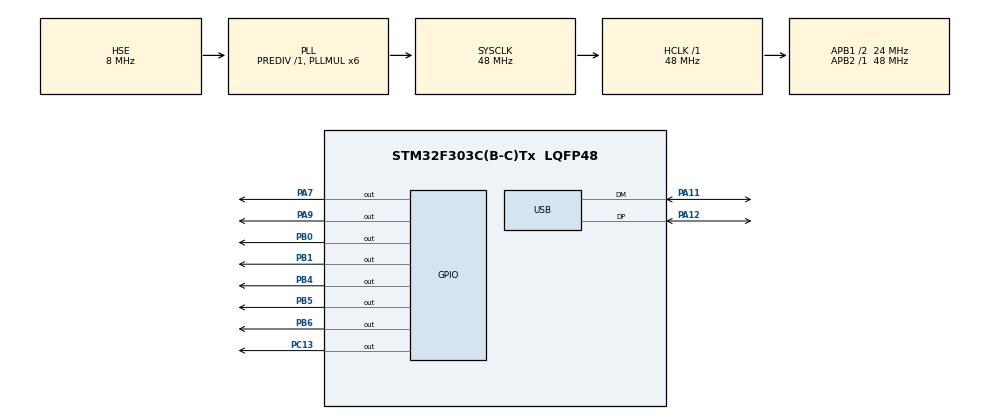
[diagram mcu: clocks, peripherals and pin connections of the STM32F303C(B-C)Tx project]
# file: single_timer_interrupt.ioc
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Mcu.Family=STM32F3
Mcu.Name=STM32F303C(B-C)Tx
Mcu.Package=LQFP48
NVIC.PriorityGroup=NVIC_PRIORITYGROUP_4
NVIC.TIM8_UP_IRQn=true\:0\:0\:false\:false\:true\:true\:true\:true
NVIC.USB_LP_CAN_RX0_IRQn=true\:0\:0\:false\:false\:true\:false\:true\:true
PA11.Mode=Device
PA11.Signal=USB_DM
PA12.Mode=Device
PA12.Signal=USB_DP
PA7.Signal=GPIO_Output
PA9.Signal=GPIO_Output
PB0.Signal=GPIO_Output
PB1.Signal=GPIO_Output
PB4.Signal=GPIO_Output
PB5.Signal=GPIO_Output
PB6.Signal=GPIO_Output
PC13.Signal=GPIO_Output
PF0-OSC_IN.Mode=HSE-External-Oscillator
PF0-OSC_IN.Signal=RCC_OSC_IN
PF1-OSC_OUT.Mode=HSE-External-Oscillator
PF1-OSC_OUT.Signal=RCC_OSC_OUT
ProjectManager.HeapSize=0x200
ProjectManager.StackSize=0x400
ProjectManager.TargetToolchain=CMake
RCC.AHBFreq_Value=48000000
RCC.APB1CLKDivider=RCC_HCLK_DIV2
RCC.APB1Freq_Value=24000000
RCC.APB1TimFreq_Value=48000000
RCC.APB2Freq_Value=48000000
RCC.APB2TimFreq_Value=48000000
RCC.CortexFreq_Value=48000000
RCC.HCLKFreq_Value=48000000
RCC.HSE_VALUE=8000000
RCC.HSI_VALUE=8000000
RCC.LSE_VALUE=32768
RCC.PLLMUL=RCC_PLL_MUL6
RCC.SYSCLKFreq_VALUE=48000000
RCC.SYSCLKSourceVirtual=RCC_SYSCLKSOURCE_PLLCLK
RCC.USBFreq_Value=48000000
TIM8.Period=65535
TIM8.TIM_MasterOutputTrigger=TIM_TRGO_UPDATE
USB_DEVICE.CLASS_NAME_FS=CDC
USB_DEVICE.VirtualMode=Cdc
USB_DEVICE.VirtualModeFS=Cdc_FS
VP_TIM8_VS_ClockSourceINT.Mode=Internal
VP_USB_DEVICE_VS_USB_DEVICE_CDC_FS.Mode=CDC_FS
board=custom

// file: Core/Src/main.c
/* USER CODE BEGIN Header */
/**
  ******************************************************************************
  * @file           : main.c
  * @brief          : Main program body
  ******************************************************************************
  * @attention
  *
  * Copyright (c) 2024 STMicroelectronics.
  * All rights reserved.
  *
  * This software is licensed under terms that can be found in the LICENSE file
  * in the root directory of this software component.
  * If no LICENSE file comes with this software, it is provided AS-IS.
  *
  ******************************************************************************
  */
/* USER CODE END Header */
#include "main.h"
#include "usb_device.h"

TIM_HandleTypeDef htim8;

void SystemClock_Config(void);
static void MX_GPIO_Init(void);
static void MX_TIM8_Init(void);

int main(void)
{

  /* MCU Configuration--------------------------------------------------------*/

  /* Reset of all peripherals, Initializes the Flash interface and the Systick. */
  HAL_Init();

  /* Configure the system clock */
  SystemClock_Config();

  /* Initialize all configured peripherals */
  MX_GPIO_Init();
  MX_TIM8_Init();
  MX_USB_DEVICE_Init();
  /* USER CODE BEGIN 2 */
  HAL_GPIO_WritePin(GPIOA, GPIO_PIN_9, GPIO_PIN_SET);
  for (int i=0; i<6; i++)
  {
    printf("BLINK\r\n");
    HAL_Delay(1000);
    HAL_GPIO_TogglePin(GPIOC, GPIO_PIN_13);
  }
  // HAL_TIM_Base_MspInit(&htim8); Already called in the initialization
  HAL_TIM_Base_Start_IT(&htim8);
  /* USER CODE END 2 */

  /* Infinite loop */
  /* USER CODE BEGIN WHILE */
  while (1)
  {

    HAL_Delay(1000);
    HAL_GPIO_TogglePin(GPIOC, GPIO_PIN_13);
    /* USER CODE END WHILE */

  }
}

void SystemClock_Config(void)
{
  RCC_OscInitTypeDef RCC_OscInitStruct = {0};
  RCC_ClkInitTypeDef RCC_ClkInitStruct = {0};
  RCC_PeriphCLKInitTypeDef PeriphClkInit = {0};

  /** Initializes the RCC Oscillators according to the specified parameters
  * in the RCC_OscInitTypeDef structure.
  */
  RCC_OscInitStruct.OscillatorType = RCC_OSCILLATORTYPE_HSE;
  RCC_OscInitStruct.HSEState = RCC_HSE_ON;
  RCC_OscInitStruct.HSEPredivValue = RCC_HSE_PREDIV_DIV1;
  RCC_OscInitStruct.HSIState = RCC_HSI_ON;
  RCC_OscInitStruct.PLL.PLLState = RCC_PLL_ON;
  RCC_OscInitStruct.PLL.PLLSource = RCC_PLLSOURCE_HSE;
  RCC_OscInitStruct.PLL.PLLMUL = RCC_PLL_MUL6;
  if (HAL_RCC_OscConfig(&RCC_OscInitStruct) != HAL_OK)
  {
    Error_Handler();
  }

  /** Initializes the CPU, AHB and APB buses clocks
  */
  RCC_ClkInitStruct.ClockType = RCC_CLOCKTYPE_HCLK|RCC_CLOCKTYPE_SYSCLK
                              |RCC_CLOCKTYPE_PCLK1|RCC_CLOCKTYPE_PCLK2;
  RCC_ClkInitStruct.SYSCLKSource = RCC_SYSCLKSOURCE_PLLCLK;
  RCC_ClkInitStruct.AHBCLKDivider = RCC_SYSCLK_DIV1;
  RCC_ClkInitStruct.APB1CLKDivider = RCC_HCLK_DIV2;
  RCC_ClkInitStruct.APB2CLKDivider = RCC_HCLK_DIV1;

  if (HAL_RCC_ClockConfig(&RCC_ClkInitStruct, FLASH_LATENCY_1) != HAL_OK)
  {
    Error_Handler();
  }
  PeriphClkInit.PeriphClockSelection = RCC_PERIPHCLK_USB|RCC_PERIPHCLK_TIM8;
  PeriphClkInit.USBClockSelection = RCC_USBCLKSOURCE_PLL;
  PeriphClkInit.Tim8ClockSelection = RCC_TIM8CLK_HCLK;
  if (HAL_RCCEx_PeriphCLKConfig(&PeriphClkInit) != HAL_OK)
  {
    Error_Handler();
  }
}

static void MX_TIM8_Init(void)
{

  TIM_ClockConfigTypeDef sClockSourceConfig = {0};
  TIM_MasterConfigTypeDef sMasterConfig = {0};

  htim8.Instance = TIM8;
  htim8.Init.Prescaler = 0;
  htim8.Init.CounterMode = TIM_COUNTERMODE_UP;
  htim8.Init.Period = 65535;
  htim8.Init.ClockDivision = TIM_CLOCKDIVISION_DIV1;
  htim8.Init.RepetitionCounter = 0;
  htim8.Init.AutoReloadPreload = TIM_AUTORELOAD_PRELOAD_DISABLE;
  if (HAL_TIM_Base_Init(&htim8) != HAL_OK)
  {
    Error_Handler();
  }
  sClockSourceConfig.ClockSource = TIM_CLOCKSOURCE_INTERNAL;
  if (HAL_TIM_ConfigClockSource(&htim8, &sClockSourceConfig) != HAL_OK)
  {
    Error_Handler();
  }
  sMasterConfig.MasterOutputTrigger = TIM_TRGO_UPDATE;
  sMasterConfig.MasterOutputTrigger2 = TIM_TRGO2_RESET;
  sMasterConfig.MasterSlaveMode = TIM_MASTERSLAVEMODE_DISABLE;
  if (HAL_TIMEx_MasterConfigSynchronization(&htim8, &sMasterConfig) != HAL_OK)
  {
    Error_Handler();
  }

}

static void MX_GPIO_Init(void)
{
  GPIO_InitTypeDef GPIO_InitStruct = {0};

  /* GPIO Ports Clock Enable */
  __HAL_RCC_GPIOC_CLK_ENABLE();
  __HAL_RCC_GPIOF_CLK_ENABLE();
  __HAL_RCC_GPIOA_CLK_ENABLE();
  __HAL_RCC_GPIOB_CLK_ENABLE();

  /*Configure GPIO pin Output Level */
  HAL_GPIO_WritePin(GPIOC, GPIO_PIN_13, GPIO_PIN_RESET);

  /*Configure GPIO pin Output Level */
  HAL_GPIO_WritePin(GPIOA, GPIO_PIN_7|GPIO_PIN_9, GPIO_PIN_RESET);

  /*Configure GPIO pin Output Level */
  HAL_GPIO_WritePin(GPIOB, GPIO_PIN_0|GPIO_PIN_1|GPIO_PIN_4|GPIO_PIN_5
                          |GPIO_PIN_6, GPIO_PIN_RESET);

  /*Configure GPIO pin : PC13 */
  GPIO_InitStruct.Pin = GPIO_PIN_13;
  GPIO_InitStruct.Mode = GPIO_MODE_OUTPUT_PP;
  GPIO_InitStruct.Pull = GPIO_NOPULL;
  GPIO_InitStruct.Speed = GPIO_SPEED_FREQ_LOW;
  HAL_GPIO_Init(GPIOC, &GPIO_InitStruct);

  /*Configure GPIO pins : PA7 PA9 */
  GPIO_InitStruct.Pin = GPIO_PIN_7|GPIO_PIN_9;
  GPIO_InitStruct.Mode = GPIO_MODE_OUTPUT_PP;
  GPIO_InitStruct.Pull = GPIO_NOPULL;
  GPIO_InitStruct.Speed = GPIO_SPEED_FREQ_LOW;
  HAL_GPIO_Init(GPIOA, &GPIO_InitStruct);

  /*Configure GPIO pins : PB0 PB1 PB4 PB5
                           PB6 */
  GPIO_InitStruct.Pin = GPIO_PIN_0|GPIO_PIN_1|GPIO_PIN_4|GPIO_PIN_5
                          |GPIO_PIN_6;
  GPIO_InitStruct.Mode = GPIO_MODE_OUTPUT_PP;
  GPIO_InitStruct.Pull = GPIO_NOPULL;
  GPIO_InitStruct.Speed = GPIO_SPEED_FREQ_LOW;
  HAL_GPIO_Init(GPIOB, &GPIO_InitStruct);

}

void Error_Handler(void)
{
  __disable_irq();
  while (1)
  {
  }
}
